VERSION ""

NS_ :

BS_:

BU_:

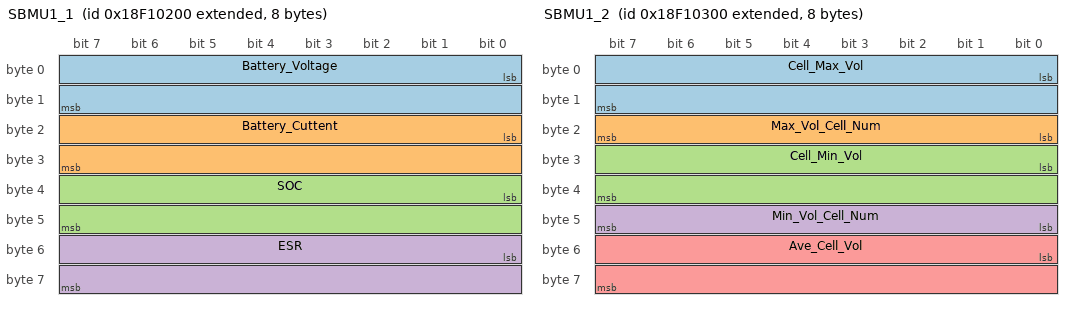
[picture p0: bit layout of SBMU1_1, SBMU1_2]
BO_ 2565931520 SBMU1_1: 8 Vector__XXX
 SG_ Battery_Voltage : 0|16@1+ (0.05,0) [0|255] "V" Vector__XXX
 SG_ Battery_Cuttent : 16|16@1+ (0.05,-1600) [0|255] "A" Vector__XXX
 SG_ SOC : 32|16@1+ (0.1,0) [0|255] "%" Vector__XXX
 SG_ ESR : 48|16@1+ (0.1,0) [0|255] "m次" Vector__XXX

BO_ 2565931776 SBMU1_2: 8 Vector__XXX
 SG_ Cell_Max_Vol : 0|16@1+ (0.001,0) [0|255] "V" Vector__XXX
 SG_ Max_Vol_Cell_Num : 16|8@1+ (1,0) [0|255] "" Vector__XXX
 SG_ Cell_Min_Vol : 24|16@1+ (0.001,0) [0|255] "V" Vector__XXX
 SG_ Min_Vol_Cell_Num : 47|8@0+ (1,0) [0|255] "" Vector__XXX
 SG_ Ave_Cell_Vol : 48|16@1+ (0.001,0) [0|255] "V" Vector__XXX

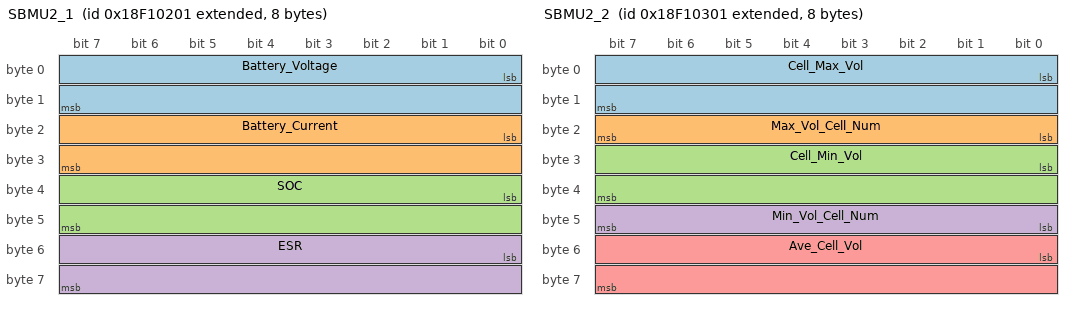
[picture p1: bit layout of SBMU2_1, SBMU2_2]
BO_ 2565931521 SBMU2_1: 8 Vector__XXX
 SG_ Battery_Voltage : 0|16@1+ (0.05,0) [0|255] "V" Vector__XXX
 SG_ Battery_Current : 16|16@1+ (0.05,-1600) [0|255] "A" Vector__XXX
 SG_ SOC : 32|16@1+ (0.1,0) [0|255] "%" Vector__XXX
 SG_ ESR : 48|16@1+ (0.1,0) [0|255] "m次" Vector__XXX

BO_ 2565931777 SBMU2_2: 8 Vector__XXX
 SG_ Cell_Max_Vol : 0|16@1+ (0.001,0) [0|255] "V" Vector__XXX
 SG_ Max_Vol_Cell_Num : 16|8@1+ (1,0) [0|255] "" Vector__XXX
 SG_ Cell_Min_Vol : 24|16@1+ (0.001,0) [0|255] "V" Vector__XXX
 SG_ Min_Vol_Cell_Num : 47|8@0+ (1,0) [0|255] "" Vector__XXX
 SG_ Ave_Cell_Vol : 48|16@1+ (0.001,0) [0|255] "V" Vector__XXX

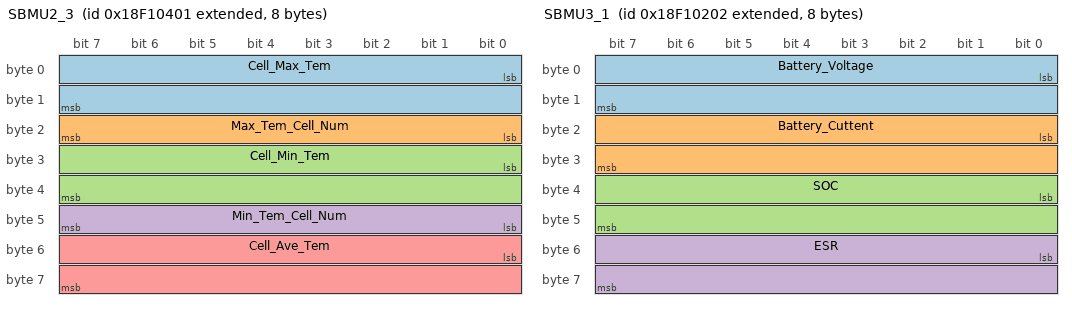
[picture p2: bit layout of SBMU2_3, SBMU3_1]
BO_ 2565932033 SBMU2_3: 8 Vector__XXX
 SG_ Cell_Max_Tem : 0|16@1+ (0.1,-40) [0|255] "⊥" Vector__XXX
 SG_ Max_Tem_Cell_Num : 23|8@0+ (1,0) [0|255] "" Vector__XXX
 SG_ Cell_Min_Tem : 24|16@1+ (0.1,-40) [0|255] "⊥" Vector__XXX
 SG_ Min_Tem_Cell_Num : 47|8@0+ (1,0) [0|255] "" Vector__XXX
 SG_ Cell_Ave_Tem : 48|16@1+ (0.1,-40) [0|255] "⊥" Vector__XXX

BO_ 2565931522 SBMU3_1: 8 Vector__XXX
 SG_ Battery_Voltage : 0|16@1+ (0.05,0) [0|255] "V" Vector__XXX
 SG_ Battery_Cuttent : 16|16@1+ (0.05,-1600) [0|255] "A" Vector__XXX
 SG_ SOC : 32|16@1+ (0.1,0) [0|255] "%" Vector__XXX
 SG_ ESR : 48|16@1+ (0.1,0) [0|255] "m次" Vector__XXX

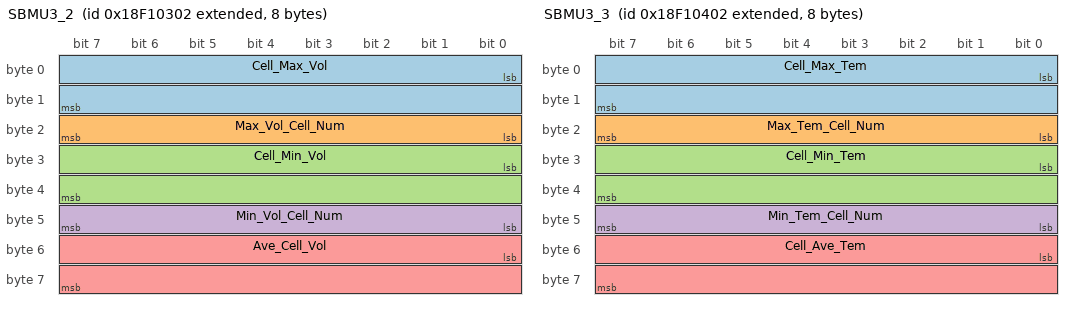
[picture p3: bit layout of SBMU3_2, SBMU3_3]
BO_ 2565931778 SBMU3_2: 8 Vector__XXX
 SG_ Cell_Max_Vol : 0|16@1+ (0.001,0) [0|255] "V" Vector__XXX
 SG_ Max_Vol_Cell_Num : 16|8@1+ (1,0) [0|255] "" Vector__XXX
 SG_ Cell_Min_Vol : 24|16@1+ (0.001,0) [0|255] "V" Vector__XXX
 SG_ Min_Vol_Cell_Num : 47|8@0+ (1,0) [0|255] "" Vector__XXX
 SG_ Ave_Cell_Vol : 48|16@1+ (0.001,0) [0|255] "V" Vector__XXX

BO_ 2565932034 SBMU3_3: 8 Vector__XXX
 SG_ Cell_Max_Tem : 0|16@1+ (0.1,-40) [0|255] "⊥" Vector__XXX
 SG_ Max_Tem_Cell_Num : 23|8@0+ (1,0) [0|255] "" Vector__XXX
 SG_ Cell_Min_Tem : 24|16@1+ (0.1,-40) [0|255] "⊥" Vector__XXX
 SG_ Min_Tem_Cell_Num : 47|8@0+ (1,0) [0|255] "" Vector__XXX
 SG_ Cell_Ave_Tem : 48|16@1+ (0.1,-40) [0|255] "⊥" Vector__XXX

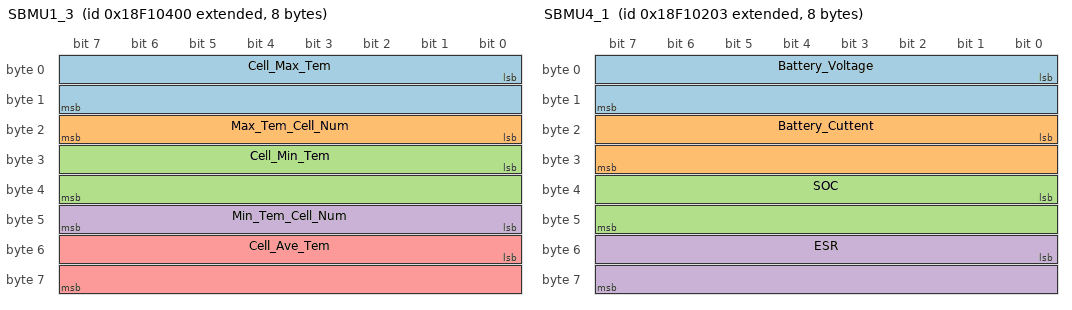
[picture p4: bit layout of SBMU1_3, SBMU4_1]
BO_ 2565932032 SBMU1_3: 8 Vector__XXX
 SG_ Cell_Max_Tem : 0|16@1+ (0.1,-40) [0|255] "⊥" Vector__XXX
 SG_ Max_Tem_Cell_Num : 23|8@0+ (1,0) [0|255] "" Vector__XXX
 SG_ Cell_Min_Tem : 24|16@1+ (0.1,-40) [0|255] "⊥" Vector__XXX
 SG_ Min_Tem_Cell_Num : 47|8@0+ (1,0) [0|255] "" Vector__XXX
 SG_ Cell_Ave_Tem : 48|16@1+ (0.1,-40) [0|255] "⊥" Vector__XXX

BO_ 2565931523 SBMU4_1: 8 Vector__XXX
 SG_ Battery_Voltage : 0|16@1+ (0.05,0) [0|255] "V" Vector__XXX
 SG_ Battery_Cuttent : 16|16@1+ (0.05,-1600) [0|255] "A" Vector__XXX
 SG_ SOC : 32|16@1+ (0.1,0) [0|255] "%" Vector__XXX
 SG_ ESR : 48|16@1+ (0.1,0) [0|255] "m次" Vector__XXX

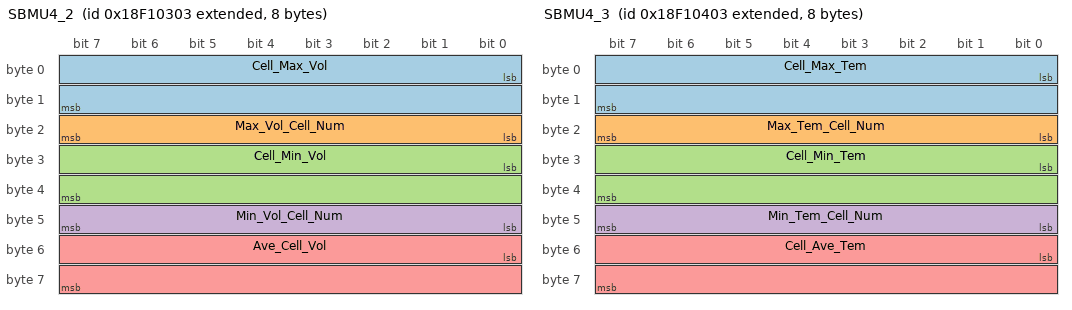
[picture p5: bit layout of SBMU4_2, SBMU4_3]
BO_ 2565931779 SBMU4_2: 8 Vector__XXX
 SG_ Cell_Max_Vol : 0|16@1+ (0.001,0) [0|255] "V" Vector__XXX
 SG_ Max_Vol_Cell_Num : 16|8@1+ (1,0) [0|255] "" Vector__XXX
 SG_ Cell_Min_Vol : 24|16@1+ (0.001,0) [0|255] "V" Vector__XXX
 SG_ Min_Vol_Cell_Num : 47|8@0+ (1,0) [0|255] "" Vector__XXX
 SG_ Ave_Cell_Vol : 48|16@1+ (0.001,0) [0|255] "V" Vector__XXX

BO_ 2565932035 SBMU4_3: 8 Vector__XXX
 SG_ Cell_Max_Tem : 0|16@1+ (0.1,-40) [0|255] "⊥" Vector__XXX
 SG_ Max_Tem_Cell_Num : 23|8@0+ (1,0) [0|255] "" Vector__XXX
 SG_ Cell_Min_Tem : 24|16@1+ (0.1,-40) [0|255] "⊥" Vector__XXX
 SG_ Min_Tem_Cell_Num : 47|8@0+ (1,0) [0|255] "" Vector__XXX
 SG_ Cell_Ave_Tem : 48|16@1+ (0.1,-40) [0|255] "⊥" Vector__XXX
